AUTOSAR XML (schema 4-0-3)
standard types defined: Boolean, UInt16, UInt8
package /AUTOSAR_Platform/DataConstrs
  range DC_Boolean: raw 0..1
  range DC_UInt16: raw 0..65535
  range DC_UInt8: raw 0..255
package /PATAC/MSM/ComponentTypes
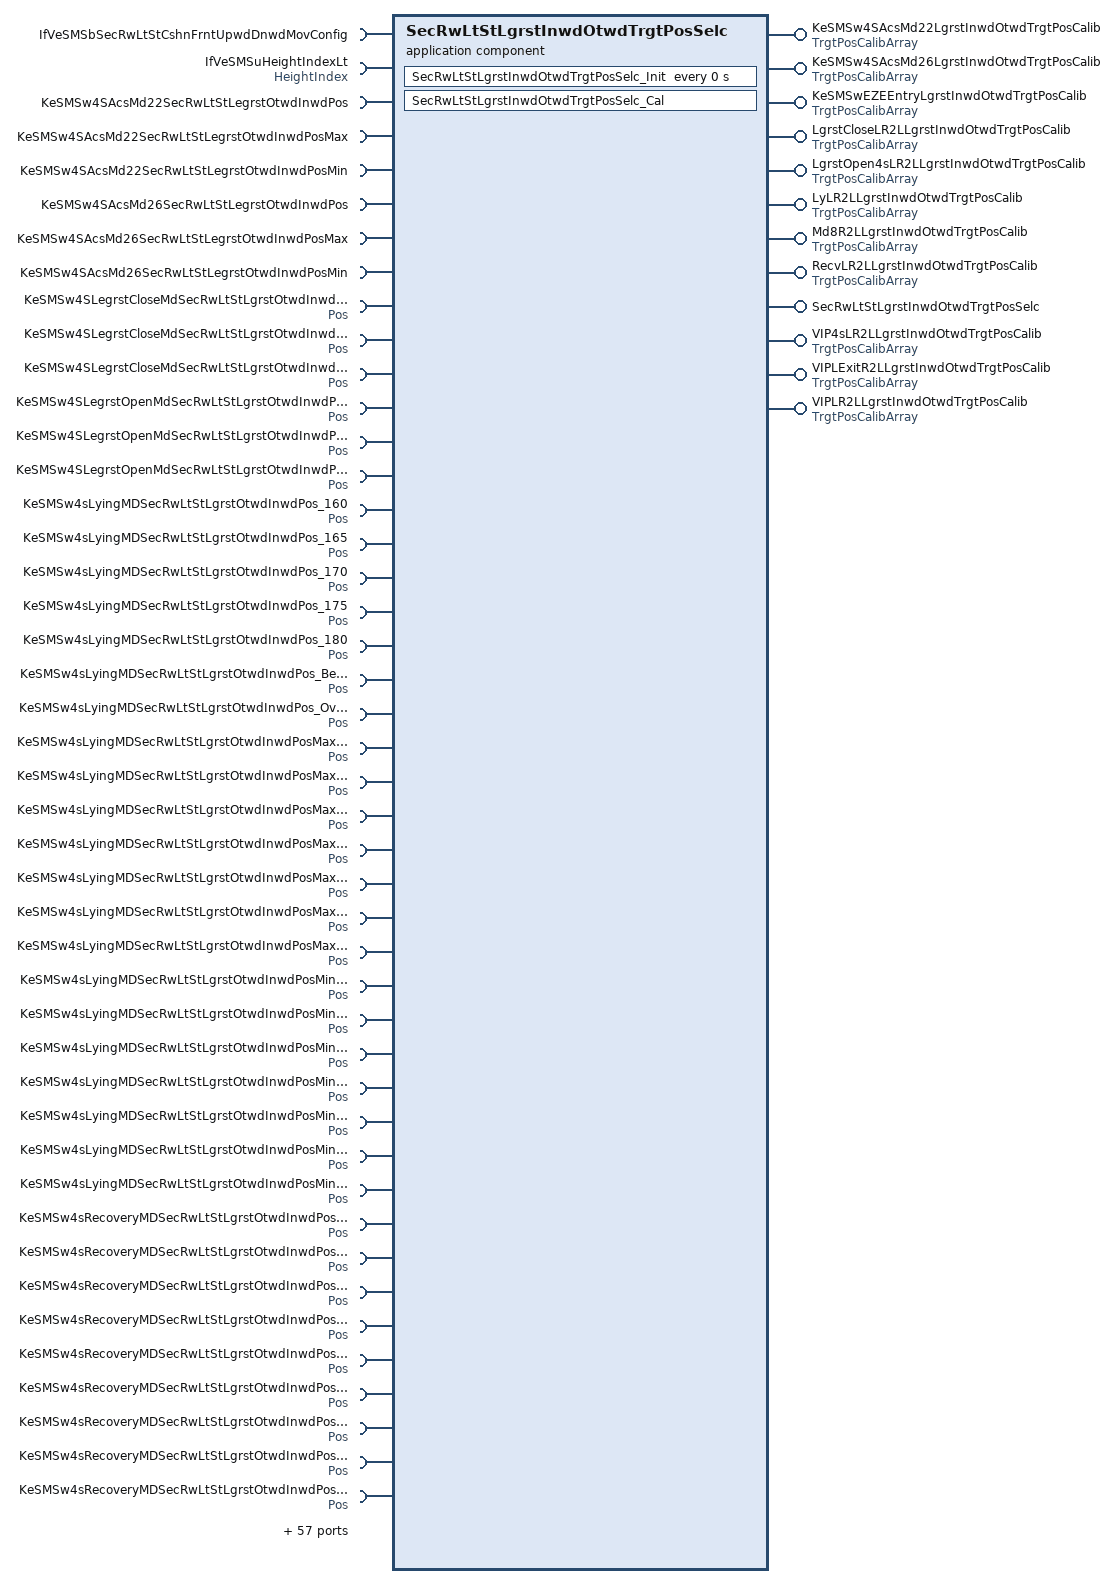
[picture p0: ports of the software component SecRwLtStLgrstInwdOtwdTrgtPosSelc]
  application sw component type SecRwLtStLgrstInwdOtwdTrgtPosSelc
    12 x provide port:
      KeSMSw4SAcsMd22LgrstInwdOtwdTrgtPosCalib: nonqueued-sender-com-spec{data-element=TrgtPosArray, init-value=[4095, 4095, 4095]}, provided-interface=TrgtPosCalibArray
      KeSMSw4SAcsMd26LgrstInwdOtwdTrgtPosCalib: nonqueued-sender-com-spec{data-element=TrgtPosArray, init-value=[4095, 4095, 4095]}, provided-interface=TrgtPosCalibArray
      KeSMSwEZEEntryLgrstInwdOtwdTrgtPosCalib: nonqueued-sender-com-spec{data-element=TrgtPosArray, init-value=[4095, 4095, 4095]}, provided-interface=TrgtPosCalibArray
      LgrstCloseLR2LLgrstInwdOtwdTrgtPosCalib: nonqueued-sender-com-spec{data-element=TrgtPosArray, init-value=[4095, 4095, 4095]}, provided-interface=TrgtPosCalibArray
      LgrstOpen4sLR2LLgrstInwdOtwdTrgtPosCalib: nonqueued-sender-com-spec{data-element=TrgtPosArray, init-value=[4095, 4095, 4095]}, provided-interface=TrgtPosCalibArray
      LyLR2LLgrstInwdOtwdTrgtPosCalib: nonqueued-sender-com-spec{data-element=TrgtPosArray, init-value=[4095, 4095, 4095]}, provided-interface=TrgtPosCalibArray
      Md8R2LLgrstInwdOtwdTrgtPosCalib: nonqueued-sender-com-spec{data-element=TrgtPosArray, init-value=[4095, 4095, 4095]}, provided-interface=TrgtPosCalibArray
      RecvLR2LLgrstInwdOtwdTrgtPosCalib: nonqueued-sender-com-spec{data-element=TrgtPosArray, init-value=[4095, 4095, 4095]}, provided-interface=TrgtPosCalibArray
      SecRwLtStLgrstInwdOtwdTrgtPosSelc: server-com-spec{operation=Cal, queue-length=1}, provided-interface=SecRwLtStLgrstInwdOtwdTrgtPosSelc
      VIP4sLR2LLgrstInwdOtwdTrgtPosCalib: nonqueued-sender-com-spec{data-element=TrgtPosArray, init-value=[4095, 4095, 4095]}, provided-interface=TrgtPosCalibArray
      VIPLExitR2LLgrstInwdOtwdTrgtPosCalib: nonqueued-sender-com-spec{data-element=TrgtPosArray, init-value=[4095, 4095, 4095]}, provided-interface=TrgtPosCalibArray
      VIPLR2LLgrstInwdOtwdTrgtPosCalib: nonqueued-sender-com-spec{data-element=TrgtPosArray, init-value=[4095, 4095, 4095]}, provided-interface=TrgtPosCalibArray
    101 x require port:
      IfVeSMSbSecRwLtStCshnFrntUpwdDnwdMovConfig: nonqueued-receiver-com-spec{data-element=IfVeSMSbSecRwLtStCshnFrntUpwdDnwdMovConfig/Val, filter=data-filter-type=ALWAYS, init-value=0}, required-interface=IfVeSMSbSecRwLtStCshnFrntUpwdDnwdMovConfig
      IfVeSMSuHeightIndexLt: nonqueued-receiver-com-spec{data-element=HeightIndex/Val, filter=data-filter-type=ALWAYS, init-value=0}, required-interface=HeightIndex
      KeSMSw4SAcsMd22SecRwLtStLegrstOtwdInwdPos: parameter-require-com-spec{init-value=0, parameter=KeSMSw4SAcsMd22SecRwLtStLegrstOtwdInwdPos/Val}, required-interface=KeSMSw4SAcsMd22SecRwLtStLegrstOtwdInwdPos
      KeSMSw4SAcsMd22SecRwLtStLegrstOtwdInwdPosMax: parameter-require-com-spec{init-value=0, parameter=KeSMSw4SAcsMd22SecRwLtStLegrstOtwdInwdPosMax/Val}, required-interface=KeSMSw4SAcsMd22SecRwLtStLegrstOtwdInwdPosMax
      KeSMSw4SAcsMd22SecRwLtStLegrstOtwdInwdPosMin: parameter-require-com-spec{init-value=0, parameter=KeSMSw4SAcsMd22SecRwLtStLegrstOtwdInwdPosMin/Val}, required-interface=KeSMSw4SAcsMd22SecRwLtStLegrstOtwdInwdPosMin
      KeSMSw4SAcsMd26SecRwLtStLegrstOtwdInwdPos: parameter-require-com-spec{init-value=0, parameter=KeSMSw4SAcsMd26SecRwLtStLegrstOtwdInwdPos/Val}, required-interface=KeSMSw4SAcsMd26SecRwLtStLegrstOtwdInwdPos
      KeSMSw4SAcsMd26SecRwLtStLegrstOtwdInwdPosMax: parameter-require-com-spec{init-value=0, parameter=KeSMSw4SAcsMd26SecRwLtStLegrstOtwdInwdPosMax/Val}, required-interface=KeSMSw4SAcsMd26SecRwLtStLegrstOtwdInwdPosMax
      KeSMSw4SAcsMd26SecRwLtStLegrstOtwdInwdPosMin: parameter-require-com-spec{init-value=0, parameter=KeSMSw4SAcsMd26SecRwLtStLegrstOtwdInwdPosMin/Val}, required-interface=KeSMSw4SAcsMd26SecRwLtStLegrstOtwdInwdPosMin
      KeSMSw4SLegrstCloseMdSecRwLtStLgrstOtwdInwdPos: parameter-require-com-spec{init-value=0, parameter=Pos/Val}, required-interface=Pos
      KeSMSw4SLegrstCloseMdSecRwLtStLgrstOtwdInwdPosMax: parameter-require-com-spec{init-value=0, parameter=Pos/Val}, required-interface=Pos
      KeSMSw4SLegrstCloseMdSecRwLtStLgrstOtwdInwdPosMin: parameter-require-com-spec{init-value=0, parameter=Pos/Val}, required-interface=Pos
      KeSMSw4SLegrstOpenMdSecRwLtStLgrstOtwdInwdPos: parameter-require-com-spec{init-value=0, parameter=Pos/Val}, required-interface=Pos
      KeSMSw4SLegrstOpenMdSecRwLtStLgrstOtwdInwdPosMax: parameter-require-com-spec{init-value=0, parameter=Pos/Val}, required-interface=Pos
      KeSMSw4SLegrstOpenMdSecRwLtStLgrstOtwdInwdPosMin: parameter-require-com-spec{init-value=0, parameter=Pos/Val}, required-interface=Pos
      KeSMSw4sLyingMDSecRwLtStLgrstOtwdInwdPos_160: parameter-require-com-spec{init-value=0, parameter=Pos/Val}, required-interface=Pos
      KeSMSw4sLyingMDSecRwLtStLgrstOtwdInwdPos_165: parameter-require-com-spec{init-value=0, parameter=Pos/Val}, required-interface=Pos
      KeSMSw4sLyingMDSecRwLtStLgrstOtwdInwdPos_170: parameter-require-com-spec{init-value=0, parameter=Pos/Val}, required-interface=Pos
      KeSMSw4sLyingMDSecRwLtStLgrstOtwdInwdPos_175: parameter-require-com-spec{init-value=0, parameter=Pos/Val}, required-interface=Pos
      KeSMSw4sLyingMDSecRwLtStLgrstOtwdInwdPos_180: parameter-require-com-spec{init-value=0, parameter=Pos/Val}, required-interface=Pos
      KeSMSw4sLyingMDSecRwLtStLgrstOtwdInwdPos_Below160: parameter-require-com-spec{init-value=0, parameter=Pos/Val}, required-interface=Pos
      KeSMSw4sLyingMDSecRwLtStLgrstOtwdInwdPos_Over180: parameter-require-com-spec{init-value=0, parameter=Pos/Val}, required-interface=Pos
      KeSMSw4sLyingMDSecRwLtStLgrstOtwdInwdPosMax_160: parameter-require-com-spec{init-value=0, parameter=Pos/Val}, required-interface=Pos
      KeSMSw4sLyingMDSecRwLtStLgrstOtwdInwdPosMax_165: parameter-require-com-spec{init-value=0, parameter=Pos/Val}, required-interface=Pos
      KeSMSw4sLyingMDSecRwLtStLgrstOtwdInwdPosMax_170: parameter-require-com-spec{init-value=0, parameter=Pos/Val}, required-interface=Pos
      KeSMSw4sLyingMDSecRwLtStLgrstOtwdInwdPosMax_175: parameter-require-com-spec{init-value=0, parameter=Pos/Val}, required-interface=Pos
      KeSMSw4sLyingMDSecRwLtStLgrstOtwdInwdPosMax_180: parameter-require-com-spec{init-value=0, parameter=Pos/Val}, required-interface=Pos
      KeSMSw4sLyingMDSecRwLtStLgrstOtwdInwdPosMax_Below160: parameter-require-com-spec{init-value=0, parameter=Pos/Val}, required-interface=Pos
      KeSMSw4sLyingMDSecRwLtStLgrstOtwdInwdPosMax_Over180: parameter-require-com-spec{init-value=0, parameter=Pos/Val}, required-interface=Pos
      KeSMSw4sLyingMDSecRwLtStLgrstOtwdInwdPosMin_160: parameter-require-com-spec{init-value=0, parameter=Pos/Val}, required-interface=Pos
      KeSMSw4sLyingMDSecRwLtStLgrstOtwdInwdPosMin_165: parameter-require-com-spec{init-value=0, parameter=Pos/Val}, required-interface=Pos
      KeSMSw4sLyingMDSecRwLtStLgrstOtwdInwdPosMin_170: parameter-require-com-spec{init-value=0, parameter=Pos/Val}, required-interface=Pos
      KeSMSw4sLyingMDSecRwLtStLgrstOtwdInwdPosMin_175: parameter-require-com-spec{init-value=0, parameter=Pos/Val}, required-interface=Pos
      KeSMSw4sLyingMDSecRwLtStLgrstOtwdInwdPosMin_180: parameter-require-com-spec{init-value=0, parameter=Pos/Val}, required-interface=Pos
      KeSMSw4sLyingMDSecRwLtStLgrstOtwdInwdPosMin_Below160: parameter-require-com-spec{init-value=0, parameter=Pos/Val}, required-interface=Pos
      KeSMSw4sLyingMDSecRwLtStLgrstOtwdInwdPosMin_Over180: parameter-require-com-spec{init-value=0, parameter=Pos/Val}, required-interface=Pos
      KeSMSw4sRecoveryMDSecRwLtStLgrstOtwdInwdPos_160: parameter-require-com-spec{init-value=0, parameter=Pos/Val}, required-interface=Pos
      KeSMSw4sRecoveryMDSecRwLtStLgrstOtwdInwdPos_165: parameter-require-com-spec{init-value=0, parameter=Pos/Val}, required-interface=Pos
      KeSMSw4sRecoveryMDSecRwLtStLgrstOtwdInwdPos_170: parameter-require-com-spec{init-value=0, parameter=Pos/Val}, required-interface=Pos
      KeSMSw4sRecoveryMDSecRwLtStLgrstOtwdInwdPos_175: parameter-require-com-spec{init-value=0, parameter=Pos/Val}, required-interface=Pos
      KeSMSw4sRecoveryMDSecRwLtStLgrstOtwdInwdPos_180: parameter-require-com-spec{init-value=0, parameter=Pos/Val}, required-interface=Pos
      KeSMSw4sRecoveryMDSecRwLtStLgrstOtwdInwdPos_Below160: parameter-require-com-spec{init-value=0, parameter=Pos/Val}, required-interface=Pos
      KeSMSw4sRecoveryMDSecRwLtStLgrstOtwdInwdPos_Over180: parameter-require-com-spec{init-value=0, parameter=Pos/Val}, required-interface=Pos
      KeSMSw4sRecoveryMDSecRwLtStLgrstOtwdInwdPosMax_160: parameter-require-com-spec{init-value=0, parameter=Pos/Val}, required-interface=Pos
      KeSMSw4sRecoveryMDSecRwLtStLgrstOtwdInwdPosMax_165: parameter-require-com-spec{init-value=0, parameter=Pos/Val}, required-interface=Pos
      KeSMSw4sRecoveryMDSecRwLtStLgrstOtwdInwdPosMax_170: parameter-require-com-spec{init-value=0, parameter=Pos/Val}, required-interface=Pos
      KeSMSw4sRecoveryMDSecRwLtStLgrstOtwdInwdPosMax_175: parameter-require-com-spec{init-value=0, parameter=Pos/Val}, required-interface=Pos
      KeSMSw4sRecoveryMDSecRwLtStLgrstOtwdInwdPosMax_180: parameter-require-com-spec{init-value=0, parameter=Pos/Val}, required-interface=Pos
      KeSMSw4sRecoveryMDSecRwLtStLgrstOtwdInwdPosMax_Below160: parameter-require-com-spec{init-value=0, parameter=Pos/Val}, required-interface=Pos
      KeSMSw4sRecoveryMDSecRwLtStLgrstOtwdInwdPosMax_Over180: parameter-require-com-spec{init-value=0, parameter=Pos/Val}, required-interface=Pos
      KeSMSw4sRecoveryMDSecRwLtStLgrstOtwdInwdPosMin_160: parameter-require-com-spec{init-value=0, parameter=Pos/Val}, required-interface=Pos
      KeSMSw4sRecoveryMDSecRwLtStLgrstOtwdInwdPosMin_165: parameter-require-com-spec{init-value=0, parameter=Pos/Val}, required-interface=Pos
      KeSMSw4sRecoveryMDSecRwLtStLgrstOtwdInwdPosMin_170: parameter-require-com-spec{init-value=0, parameter=Pos/Val}, required-interface=Pos
      KeSMSw4sRecoveryMDSecRwLtStLgrstOtwdInwdPosMin_175: parameter-require-com-spec{init-value=0, parameter=Pos/Val}, required-interface=Pos
      KeSMSw4sRecoveryMDSecRwLtStLgrstOtwdInwdPosMin_180: parameter-require-com-spec{init-value=0, parameter=Pos/Val}, required-interface=Pos
      KeSMSw4sRecoveryMDSecRwLtStLgrstOtwdInwdPosMin_Below160: parameter-require-com-spec{init-value=0, parameter=Pos/Val}, required-interface=Pos
      KeSMSw4sRecoveryMDSecRwLtStLgrstOtwdInwdPosMin_Over180: parameter-require-com-spec{init-value=0, parameter=Pos/Val}, required-interface=Pos
      KeSMSw4sVIPMDSecRwLtStLgrstOtwdInwdPos_160: parameter-require-com-spec{init-value=0, parameter=Pos/Val}, required-interface=Pos
      KeSMSw4sVIPMDSecRwLtStLgrstOtwdInwdPos_165: parameter-require-com-spec{init-value=0, parameter=Pos/Val}, required-interface=Pos
      KeSMSw4sVIPMDSecRwLtStLgrstOtwdInwdPos_170: parameter-require-com-spec{init-value=0, parameter=Pos/Val}, required-interface=Pos
      KeSMSw4sVIPMDSecRwLtStLgrstOtwdInwdPos_175: parameter-require-com-spec{init-value=0, parameter=Pos/Val}, required-interface=Pos
      KeSMSw4sVIPMDSecRwLtStLgrstOtwdInwdPos_180: parameter-require-com-spec{init-value=0, parameter=Pos/Val}, required-interface=Pos
      KeSMSw4sVIPMDSecRwLtStLgrstOtwdInwdPos_Below160: parameter-require-com-spec{init-value=0, parameter=Pos/Val}, required-interface=Pos
      KeSMSw4sVIPMDSecRwLtStLgrstOtwdInwdPos_Over180: parameter-require-com-spec{init-value=0, parameter=Pos/Val}, required-interface=Pos
      KeSMSw4sVIPMDSecRwLtStLgrstOtwdInwdPosMax_160: parameter-require-com-spec{init-value=0, parameter=Pos/Val}, required-interface=Pos
      KeSMSw4sVIPMDSecRwLtStLgrstOtwdInwdPosMax_165: parameter-require-com-spec{init-value=0, parameter=Pos/Val}, required-interface=Pos
      KeSMSw4sVIPMDSecRwLtStLgrstOtwdInwdPosMax_170: parameter-require-com-spec{init-value=0, parameter=Pos/Val}, required-interface=Pos
      KeSMSw4sVIPMDSecRwLtStLgrstOtwdInwdPosMax_175: parameter-require-com-spec{init-value=0, parameter=Pos/Val}, required-interface=Pos
      KeSMSw4sVIPMDSecRwLtStLgrstOtwdInwdPosMax_180: parameter-require-com-spec{init-value=0, parameter=Pos/Val}, required-interface=Pos
      KeSMSw4sVIPMDSecRwLtStLgrstOtwdInwdPosMax_Below160: parameter-require-com-spec{init-value=0, parameter=Pos/Val}, required-interface=Pos
      KeSMSw4sVIPMDSecRwLtStLgrstOtwdInwdPosMax_Over180: parameter-require-com-spec{init-value=0, parameter=Pos/Val}, required-interface=Pos
      KeSMSw4sVIPMDSecRwLtStLgrstOtwdInwdPosMin_160: parameter-require-com-spec{init-value=0, parameter=Pos/Val}, required-interface=Pos
      KeSMSw4sVIPMDSecRwLtStLgrstOtwdInwdPosMin_165: parameter-require-com-spec{init-value=0, parameter=Pos/Val}, required-interface=Pos
      KeSMSw4sVIPMDSecRwLtStLgrstOtwdInwdPosMin_170: parameter-require-com-spec{init-value=0, parameter=Pos/Val}, required-interface=Pos
      KeSMSw4sVIPMDSecRwLtStLgrstOtwdInwdPosMin_175: parameter-require-com-spec{init-value=0, parameter=Pos/Val}, required-interface=Pos
      KeSMSw4sVIPMDSecRwLtStLgrstOtwdInwdPosMin_180: parameter-require-com-spec{init-value=0, parameter=Pos/Val}, required-interface=Pos
      KeSMSw4sVIPMDSecRwLtStLgrstOtwdInwdPosMin_Below160: parameter-require-com-spec{init-value=0, parameter=Pos/Val}, required-interface=Pos
      KeSMSw4sVIPMDSecRwLtStLgrstOtwdInwdPosMin_Over180: parameter-require-com-spec{init-value=0, parameter=Pos/Val}, required-interface=Pos
      KeSMSw6sAcsEntrySecRwLtStLgrstInwdOtwdPos: parameter-require-com-spec{init-value=4095, parameter=Pos/Val}, required-interface=Pos
      KeSMSw6sAcsEntrySecRwLtStLgrstInwdOtwdPosMax: parameter-require-com-spec{init-value=4095, parameter=Pos/Val}, required-interface=Pos
      KeSMSw6sAcsEntrySecRwLtStLgrstInwdOtwdPosMin: parameter-require-com-spec{init-value=4095, parameter=Pos/Val}, required-interface=Pos
      KeSMSw6sRecoveryMdSecRwLtStLgrstInwdOtwdPos: parameter-require-com-spec{init-value=4095, parameter=Pos/Val}, required-interface=Pos
      KeSMSw6sRecoveryMdSecRwLtStLgrstInwdOtwdPosMax: parameter-require-com-spec{init-value=4095, parameter=Pos/Val}, required-interface=Pos
      KeSMSw6sRecoveryMdSecRwLtStLgrstInwdOtwdPosMin: parameter-require-com-spec{init-value=4095, parameter=Pos/Val}, required-interface=Pos
      KeSMSw6SVIPMdSecRwLtStLgrstInwdOtwdPos: parameter-require-com-spec{init-value=4095, parameter=Pos/Val}, required-interface=Pos
      KeSMSw6SVIPMdSecRwLtStLgrstInwdOtwdPosMax: parameter-require-com-spec{init-value=4095, parameter=Pos/Val}, required-interface=Pos
      KeSMSw6SVIPMdSecRwLtStLgrstInwdOtwdPosMin: parameter-require-com-spec{init-value=4095, parameter=Pos/Val}, required-interface=Pos
      KeSMSwAcsEntrySecRwLtStLgrstInwdOtwdPos: parameter-require-com-spec{init-value=4095, parameter=Pos/Val}, required-interface=Pos
      KeSMSwAcsEntrySecRwLtStLgrstInwdOtwdPosMax: parameter-require-com-spec{init-value=4095, parameter=Pos/Val}, required-interface=Pos
      KeSMSwAcsEntrySecRwLtStLgrstInwdOtwdPosMin: parameter-require-com-spec{init-value=4095, parameter=Pos/Val}, required-interface=Pos
      KeSMSwAcsMd8SecRwLtStLgrstInwdOtwdPos: parameter-require-com-spec{init-value=0, parameter=Pos/Val}, required-interface=Pos
      KeSMSwAcsMd8SecRwLtStLgrstInwdOtwdPosMax: parameter-require-com-spec{init-value=0, parameter=Pos/Val}, required-interface=Pos
      KeSMSwAcsMd8SecRwLtStLgrstInwdOtwdPosMin: parameter-require-com-spec{init-value=0, parameter=Pos/Val}, required-interface=Pos
      KeSMSwRecoveryMdSecRwLtStLgrstInwdOtwdPos: parameter-require-com-spec{init-value=4095, parameter=Pos/Val}, required-interface=Pos
      KeSMSwRecoveryMdSecRwLtStLgrstInwdOtwdPosMax: parameter-require-com-spec{init-value=4095, parameter=Pos/Val}, required-interface=Pos
      KeSMSwRecoveryMdSecRwLtStLgrstInwdOtwdPosMin: parameter-require-com-spec{init-value=4095, parameter=Pos/Val}, required-interface=Pos
      KeSMSwVIPMdSecRwLtStLgrstInwdOtwdPos: parameter-require-com-spec{init-value=4095, parameter=Pos/Val}, required-interface=Pos
      KeSMSwVIPMdSecRwLtStLgrstInwdOtwdPosMax: parameter-require-com-spec{init-value=4095, parameter=Pos/Val}, required-interface=Pos
      KeSMSwVIPMdSecRwLtStLgrstInwdOtwdPosMin: parameter-require-com-spec{init-value=4095, parameter=Pos/Val}, required-interface=Pos
      StNumFlg: required-interface=StNumFlg
        required-com-specs:
          data-element=Is4s, filter=data-filter-type=ALWAYS, init-value=0
          data-element=Is6s, filter=data-filter-type=ALWAYS, init-value=0
          data-element=Is6s7s, filter=data-filter-type=ALWAYS, init-value=0
          data-element=Is7s, filter=data-filter-type=ALWAYS, init-value=0
      VIPL557TrgtPos: required-com-specs=[VIPL557TrgtPos/Get, VIPL557TrgtPos/Set], required-interface=VIPL557TrgtPos
      VIPLExit557TrgtPos: required-com-specs=[VIPLExit557TrgtPos/Get, VIPLExit557TrgtPos/Set], required-interface=VIPLExit557TrgtPos
    behavior SecRwLtStLgrstInwdOtwdTrgtPosSelc_InternalBehavior
      operation invoked event OIT_SecRwLtStLgrstInwdOtwdTrgtPosSelc_Cal_SecRwLtStLgrstInwdOtwdTrgtPosSelc_Cal: start-on-event=SecRwLtStLgrstInwdOtwdTrgtPosSelc_Cal, operation=SecRwLtStLgrstInwdOtwdTrgtPosSelc.Cal
      timing event SecRwLtStLgrstInwdOtwdTrgtPosSelc_InitEvent: start-on-event=SecRwLtStLgrstInwdOtwdTrgtPosSelc_Init, period=0
      runnable SecRwLtStLgrstInwdOtwdTrgtPosSelc_Cal
        data-receive-point-by-arguments:
          6 x access:
            REC_IfVeSMSbSecRwLtStCshnFrntUpwdDnwdMovConfig_Val: accessed-variable=IfVeSMSbSecRwLtStCshnFrntUpwdDnwdMovConfig.Val
            REC_IfVeSMSuHeightIndexLt_Val: accessed-variable=IfVeSMSuHeightIndexLt.Val
            REC_StNumFlg_Is4s: accessed-variable=StNumFlg.Is4s
            REC_StNumFlg_Is6s: accessed-variable=StNumFlg.Is6s
            REC_StNumFlg_Is6s7s: accessed-variable=StNumFlg.Is6s7s
            REC_StNumFlg_Is7s: accessed-variable=StNumFlg.Is7s
        data-send-points:
          11 x access:
            SEND_KeSMSw4SAcsMd22LgrstInwdOtwdTrgtPosCalib_TrgtPosArray: accessed-variable=KeSMSw4SAcsMd22LgrstInwdOtwdTrgtPosCalib.TrgtPosArray
            SEND_KeSMSw4SAcsMd26LgrstInwdOtwdTrgtPosCalib_TrgtPosArray: accessed-variable=KeSMSw4SAcsMd26LgrstInwdOtwdTrgtPosCalib.TrgtPosArray
            SEND_KeSMSwEZEEntryLgrstInwdOtwdTrgtPosCalib_TrgtPosArray: accessed-variable=KeSMSwEZEEntryLgrstInwdOtwdTrgtPosCalib.TrgtPosArray
            SEND_LgrstCloseLR2LLgrstInwdOtwdTrgtPosCalib_TrgtPosArray: accessed-variable=LgrstCloseLR2LLgrstInwdOtwdTrgtPosCalib.TrgtPosArray
            SEND_LgrstOpen4sLR2LLgrstInwdOtwdTrgtPosCalib_TrgtPosArray: accessed-variable=LgrstOpen4sLR2LLgrstInwdOtwdTrgtPosCalib.TrgtPosArray
            SEND_LyLR2LLgrstInwdOtwdTrgtPosCalib_TrgtPosArray: accessed-variable=LyLR2LLgrstInwdOtwdTrgtPosCalib.TrgtPosArray
            SEND_Md8R2LLgrstInwdOtwdTrgtPosCalib_TrgtPosArray: accessed-variable=Md8R2LLgrstInwdOtwdTrgtPosCalib.TrgtPosArray
            SEND_RecvLR2LLgrstInwdOtwdTrgtPosCalib_TrgtPosArray: accessed-variable=RecvLR2LLgrstInwdOtwdTrgtPosCalib.TrgtPosArray
            SEND_VIP4sLR2LLgrstInwdOtwdTrgtPosCalib_TrgtPosArray: accessed-variable=VIP4sLR2LLgrstInwdOtwdTrgtPosCalib.TrgtPosArray
            SEND_VIPLExitR2LLgrstInwdOtwdTrgtPosCalib_TrgtPosArray: accessed-variable=VIPLExitR2LLgrstInwdOtwdTrgtPosCalib.TrgtPosArray
            SEND_VIPLR2LLgrstInwdOtwdTrgtPosCalib_TrgtPosArray: accessed-variable=VIPLR2LLgrstInwdOtwdTrgtPosCalib.TrgtPosArray
        96 x parameter access:
          PA_KeSMSw4SAcsMd22SecRwLtStLegrstOtwdInwdPos_Val: accessed-parameter=KeSMSw4SAcsMd22SecRwLtStLegrstOtwdInwdPos.Val
          PA_KeSMSw4SAcsMd22SecRwLtStLegrstOtwdInwdPosMax_Val: accessed-parameter=KeSMSw4SAcsMd22SecRwLtStLegrstOtwdInwdPosMax.Val
          PA_KeSMSw4SAcsMd22SecRwLtStLegrstOtwdInwdPosMin_Val: accessed-parameter=KeSMSw4SAcsMd22SecRwLtStLegrstOtwdInwdPosMin.Val
          PA_KeSMSw4SAcsMd26SecRwLtStLegrstOtwdInwdPos_Val: accessed-parameter=KeSMSw4SAcsMd26SecRwLtStLegrstOtwdInwdPos.Val
          PA_KeSMSw4SAcsMd26SecRwLtStLegrstOtwdInwdPosMax_Val: accessed-parameter=KeSMSw4SAcsMd26SecRwLtStLegrstOtwdInwdPosMax.Val
          PA_KeSMSw4SAcsMd26SecRwLtStLegrstOtwdInwdPosMin_Val: accessed-parameter=KeSMSw4SAcsMd26SecRwLtStLegrstOtwdInwdPosMin.Val
          PA_KeSMSw4SLegrstCloseMdSecRwLtStLgrstOtwdInwdPos_Val: accessed-parameter=KeSMSw4SLegrstCloseMdSecRwLtStLgrstOtwdInwdPos.Val
          PA_KeSMSw4SLegrstCloseMdSecRwLtStLgrstOtwdInwdPosMax_Val: accessed-parameter=KeSMSw4SLegrstCloseMdSecRwLtStLgrstOtwdInwdPosMax.Val
          PA_KeSMSw4SLegrstCloseMdSecRwLtStLgrstOtwdInwdPosMin_Val: accessed-parameter=KeSMSw4SLegrstCloseMdSecRwLtStLgrstOtwdInwdPosMin.Val
          PA_KeSMSw4SLegrstOpenMdSecRwLtStLgrstOtwdInwdPos_Val: accessed-parameter=KeSMSw4SLegrstOpenMdSecRwLtStLgrstOtwdInwdPos.Val
          PA_KeSMSw4SLegrstOpenMdSecRwLtStLgrstOtwdInwdPosMax_Val: accessed-parameter=KeSMSw4SLegrstOpenMdSecRwLtStLgrstOtwdInwdPosMax.Val
          PA_KeSMSw4SLegrstOpenMdSecRwLtStLgrstOtwdInwdPosMin_Val: accessed-parameter=KeSMSw4SLegrstOpenMdSecRwLtStLgrstOtwdInwdPosMin.Val
          PA_KeSMSw4sLyingMDSecRwLtStLgrstOtwdInwdPos_160_Val: accessed-parameter=KeSMSw4sLyingMDSecRwLtStLgrstOtwdInwdPos_160.Val
          PA_KeSMSw4sLyingMDSecRwLtStLgrstOtwdInwdPos_165_Val: accessed-parameter=KeSMSw4sLyingMDSecRwLtStLgrstOtwdInwdPos_165.Val
          PA_KeSMSw4sLyingMDSecRwLtStLgrstOtwdInwdPos_170_Val: accessed-parameter=KeSMSw4sLyingMDSecRwLtStLgrstOtwdInwdPos_170.Val
          PA_KeSMSw4sLyingMDSecRwLtStLgrstOtwdInwdPos_175_Val: accessed-parameter=KeSMSw4sLyingMDSecRwLtStLgrstOtwdInwdPos_175.Val
          PA_KeSMSw4sLyingMDSecRwLtStLgrstOtwdInwdPos_180_Val: accessed-parameter=KeSMSw4sLyingMDSecRwLtStLgrstOtwdInwdPos_180.Val
          PA_KeSMSw4sLyingMDSecRwLtStLgrstOtwdInwdPos_Below160_Val: accessed-parameter=KeSMSw4sLyingMDSecRwLtStLgrstOtwdInwdPos_Below160.Val
          PA_KeSMSw4sLyingMDSecRwLtStLgrstOtwdInwdPos_Over180_Val: accessed-parameter=KeSMSw4sLyingMDSecRwLtStLgrstOtwdInwdPos_Over180.Val
          PA_KeSMSw4sLyingMDSecRwLtStLgrstOtwdInwdPosMax_160_Val: accessed-parameter=KeSMSw4sLyingMDSecRwLtStLgrstOtwdInwdPosMax_160.Val
          PA_KeSMSw4sLyingMDSecRwLtStLgrstOtwdInwdPosMax_165_Val: accessed-parameter=KeSMSw4sLyingMDSecRwLtStLgrstOtwdInwdPosMax_165.Val
          PA_KeSMSw4sLyingMDSecRwLtStLgrstOtwdInwdPosMax_170_Val: accessed-parameter=KeSMSw4sLyingMDSecRwLtStLgrstOtwdInwdPosMax_170.Val
          PA_KeSMSw4sLyingMDSecRwLtStLgrstOtwdInwdPosMax_175_Val: accessed-parameter=KeSMSw4sLyingMDSecRwLtStLgrstOtwdInwdPosMax_175.Val
          PA_KeSMSw4sLyingMDSecRwLtStLgrstOtwdInwdPosMax_180_Val: accessed-parameter=KeSMSw4sLyingMDSecRwLtStLgrstOtwdInwdPosMax_180.Val
          PA_KeSMSw4sLyingMDSecRwLtStLgrstOtwdInwdPosMax_Below160_Val: accessed-parameter=KeSMSw4sLyingMDSecRwLtStLgrstOtwdInwdPosMax_Below160.Val
          PA_KeSMSw4sLyingMDSecRwLtStLgrstOtwdInwdPosMax_Over180_Val: accessed-parameter=KeSMSw4sLyingMDSecRwLtStLgrstOtwdInwdPosMax_Over180.Val
          PA_KeSMSw4sLyingMDSecRwLtStLgrstOtwdInwdPosMin_160_Val: accessed-parameter=KeSMSw4sLyingMDSecRwLtStLgrstOtwdInwdPosMin_160.Val
          PA_KeSMSw4sLyingMDSecRwLtStLgrstOtwdInwdPosMin_165_Val: accessed-parameter=KeSMSw4sLyingMDSecRwLtStLgrstOtwdInwdPosMin_165.Val
          PA_KeSMSw4sLyingMDSecRwLtStLgrstOtwdInwdPosMin_170_Val: accessed-parameter=KeSMSw4sLyingMDSecRwLtStLgrstOtwdInwdPosMin_170.Val
          PA_KeSMSw4sLyingMDSecRwLtStLgrstOtwdInwdPosMin_175_Val: accessed-parameter=KeSMSw4sLyingMDSecRwLtStLgrstOtwdInwdPosMin_175.Val
          PA_KeSMSw4sLyingMDSecRwLtStLgrstOtwdInwdPosMin_180_Val: accessed-parameter=KeSMSw4sLyingMDSecRwLtStLgrstOtwdInwdPosMin_180.Val
          PA_KeSMSw4sLyingMDSecRwLtStLgrstOtwdInwdPosMin_Below160_Val: accessed-parameter=KeSMSw4sLyingMDSecRwLtStLgrstOtwdInwdPosMin_Below160.Val
          PA_KeSMSw4sLyingMDSecRwLtStLgrstOtwdInwdPosMin_Over180_Val: accessed-parameter=KeSMSw4sLyingMDSecRwLtStLgrstOtwdInwdPosMin_Over180.Val
          PA_KeSMSw4sRecoveryMDSecRwLtStLgrstOtwdInwdPos_160_Val: accessed-parameter=KeSMSw4sRecoveryMDSecRwLtStLgrstOtwdInwdPos_160.Val
          PA_KeSMSw4sRecoveryMDSecRwLtStLgrstOtwdInwdPos_165_Val: accessed-parameter=KeSMSw4sRecoveryMDSecRwLtStLgrstOtwdInwdPos_165.Val
          PA_KeSMSw4sRecoveryMDSecRwLtStLgrstOtwdInwdPos_170_Val: accessed-parameter=KeSMSw4sRecoveryMDSecRwLtStLgrstOtwdInwdPos_170.Val
          PA_KeSMSw4sRecoveryMDSecRwLtStLgrstOtwdInwdPos_175_Val: accessed-parameter=KeSMSw4sRecoveryMDSecRwLtStLgrstOtwdInwdPos_175.Val
          PA_KeSMSw4sRecoveryMDSecRwLtStLgrstOtwdInwdPos_180_Val: accessed-parameter=KeSMSw4sRecoveryMDSecRwLtStLgrstOtwdInwdPos_180.Val
          PA_KeSMSw4sRecoveryMDSecRwLtStLgrstOtwdInwdPos_Below160_Val: accessed-parameter=KeSMSw4sRecoveryMDSecRwLtStLgrstOtwdInwdPos_Below160.Val
          PA_KeSMSw4sRecoveryMDSecRwLtStLgrstOtwdInwdPos_Over180_Val: accessed-parameter=KeSMSw4sRecoveryMDSecRwLtStLgrstOtwdInwdPos_Over180.Val
          PA_KeSMSw4sRecoveryMDSecRwLtStLgrstOtwdInwdPosMax_160_Val: accessed-parameter=KeSMSw4sRecoveryMDSecRwLtStLgrstOtwdInwdPosMax_160.Val
          PA_KeSMSw4sRecoveryMDSecRwLtStLgrstOtwdInwdPosMax_165_Val: accessed-parameter=KeSMSw4sRecoveryMDSecRwLtStLgrstOtwdInwdPosMax_165.Val
          PA_KeSMSw4sRecoveryMDSecRwLtStLgrstOtwdInwdPosMax_170_Val: accessed-parameter=KeSMSw4sRecoveryMDSecRwLtStLgrstOtwdInwdPosMax_170.Val
          PA_KeSMSw4sRecoveryMDSecRwLtStLgrstOtwdInwdPosMax_175_Val: accessed-parameter=KeSMSw4sRecoveryMDSecRwLtStLgrstOtwdInwdPosMax_175.Val
          PA_KeSMSw4sRecoveryMDSecRwLtStLgrstOtwdInwdPosMax_180_Val: accessed-parameter=KeSMSw4sRecoveryMDSecRwLtStLgrstOtwdInwdPosMax_180.Val
          PA_KeSMSw4sRecoveryMDSecRwLtStLgrstOtwdInwdPosMax_Below160_Val: accessed-parameter=KeSMSw4sRecoveryMDSecRwLtStLgrstOtwdInwdPosMax_Below160.Val
          PA_KeSMSw4sRecoveryMDSecRwLtStLgrstOtwdInwdPosMax_Over180_Val: accessed-parameter=KeSMSw4sRecoveryMDSecRwLtStLgrstOtwdInwdPosMax_Over180.Val
          PA_KeSMSw4sRecoveryMDSecRwLtStLgrstOtwdInwdPosMin_160_Val: accessed-parameter=KeSMSw4sRecoveryMDSecRwLtStLgrstOtwdInwdPosMin_160.Val
          PA_KeSMSw4sRecoveryMDSecRwLtStLgrstOtwdInwdPosMin_165_Val: accessed-parameter=KeSMSw4sRecoveryMDSecRwLtStLgrstOtwdInwdPosMin_165.Val
          PA_KeSMSw4sRecoveryMDSecRwLtStLgrstOtwdInwdPosMin_170_Val: accessed-parameter=KeSMSw4sRecoveryMDSecRwLtStLgrstOtwdInwdPosMin_170.Val
          PA_KeSMSw4sRecoveryMDSecRwLtStLgrstOtwdInwdPosMin_175_Val: accessed-parameter=KeSMSw4sRecoveryMDSecRwLtStLgrstOtwdInwdPosMin_175.Val
          PA_KeSMSw4sRecoveryMDSecRwLtStLgrstOtwdInwdPosMin_180_Val: accessed-parameter=KeSMSw4sRecoveryMDSecRwLtStLgrstOtwdInwdPosMin_180.Val
          PA_KeSMSw4sRecoveryMDSecRwLtStLgrstOtwdInwdPosMin_Below160_Val: accessed-parameter=KeSMSw4sRecoveryMDSecRwLtStLgrstOtwdInwdPosMin_Below160.Val
          PA_KeSMSw4sRecoveryMDSecRwLtStLgrstOtwdInwdPosMin_Over180_Val: accessed-parameter=KeSMSw4sRecoveryMDSecRwLtStLgrstOtwdInwdPosMin_Over180.Val
          PA_KeSMSw4sVIPMDSecRwLtStLgrstOtwdInwdPos_160_Val: accessed-parameter=KeSMSw4sVIPMDSecRwLtStLgrstOtwdInwdPos_160.Val
          PA_KeSMSw4sVIPMDSecRwLtStLgrstOtwdInwdPos_165_Val: accessed-parameter=KeSMSw4sVIPMDSecRwLtStLgrstOtwdInwdPos_165.Val
          PA_KeSMSw4sVIPMDSecRwLtStLgrstOtwdInwdPos_170_Val: accessed-parameter=KeSMSw4sVIPMDSecRwLtStLgrstOtwdInwdPos_170.Val
          PA_KeSMSw4sVIPMDSecRwLtStLgrstOtwdInwdPos_175_Val: accessed-parameter=KeSMSw4sVIPMDSecRwLtStLgrstOtwdInwdPos_175.Val
          PA_KeSMSw4sVIPMDSecRwLtStLgrstOtwdInwdPos_180_Val: accessed-parameter=KeSMSw4sVIPMDSecRwLtStLgrstOtwdInwdPos_180.Val
          PA_KeSMSw4sVIPMDSecRwLtStLgrstOtwdInwdPos_Below160_Val: accessed-parameter=KeSMSw4sVIPMDSecRwLtStLgrstOtwdInwdPos_Below160.Val
          PA_KeSMSw4sVIPMDSecRwLtStLgrstOtwdInwdPos_Over180_Val: accessed-parameter=KeSMSw4sVIPMDSecRwLtStLgrstOtwdInwdPos_Over180.Val
          PA_KeSMSw4sVIPMDSecRwLtStLgrstOtwdInwdPosMax_160_Val: accessed-parameter=KeSMSw4sVIPMDSecRwLtStLgrstOtwdInwdPosMax_160.Val
          PA_KeSMSw4sVIPMDSecRwLtStLgrstOtwdInwdPosMax_165_Val: accessed-parameter=KeSMSw4sVIPMDSecRwLtStLgrstOtwdInwdPosMax_165.Val
          PA_KeSMSw4sVIPMDSecRwLtStLgrstOtwdInwdPosMax_170_Val: accessed-parameter=KeSMSw4sVIPMDSecRwLtStLgrstOtwdInwdPosMax_170.Val
          PA_KeSMSw4sVIPMDSecRwLtStLgrstOtwdInwdPosMax_175_Val: accessed-parameter=KeSMSw4sVIPMDSecRwLtStLgrstOtwdInwdPosMax_175.Val
          PA_KeSMSw4sVIPMDSecRwLtStLgrstOtwdInwdPosMax_180_Val: accessed-parameter=KeSMSw4sVIPMDSecRwLtStLgrstOtwdInwdPosMax_180.Val
          PA_KeSMSw4sVIPMDSecRwLtStLgrstOtwdInwdPosMax_Below160_Val: accessed-parameter=KeSMSw4sVIPMDSecRwLtStLgrstOtwdInwdPosMax_Below160.Val
          PA_KeSMSw4sVIPMDSecRwLtStLgrstOtwdInwdPosMax_Over180_Val: accessed-parameter=KeSMSw4sVIPMDSecRwLtStLgrstOtwdInwdPosMax_Over180.Val
          PA_KeSMSw4sVIPMDSecRwLtStLgrstOtwdInwdPosMin_160_Val: accessed-parameter=KeSMSw4sVIPMDSecRwLtStLgrstOtwdInwdPosMin_160.Val
          PA_KeSMSw4sVIPMDSecRwLtStLgrstOtwdInwdPosMin_165_Val: accessed-parameter=KeSMSw4sVIPMDSecRwLtStLgrstOtwdInwdPosMin_165.Val
          PA_KeSMSw4sVIPMDSecRwLtStLgrstOtwdInwdPosMin_170_Val: accessed-parameter=KeSMSw4sVIPMDSecRwLtStLgrstOtwdInwdPosMin_170.Val
          PA_KeSMSw4sVIPMDSecRwLtStLgrstOtwdInwdPosMin_175_Val: accessed-parameter=KeSMSw4sVIPMDSecRwLtStLgrstOtwdInwdPosMin_175.Val
          PA_KeSMSw4sVIPMDSecRwLtStLgrstOtwdInwdPosMin_180_Val: accessed-parameter=KeSMSw4sVIPMDSecRwLtStLgrstOtwdInwdPosMin_180.Val
          PA_KeSMSw4sVIPMDSecRwLtStLgrstOtwdInwdPosMin_Below160_Val: accessed-parameter=KeSMSw4sVIPMDSecRwLtStLgrstOtwdInwdPosMin_Below160.Val
          PA_KeSMSw4sVIPMDSecRwLtStLgrstOtwdInwdPosMin_Over180_Val: accessed-parameter=KeSMSw4sVIPMDSecRwLtStLgrstOtwdInwdPosMin_Over180.Val
          PA_KeSMSw6sAcsEntrySecRwLtStLgrstInwdOtwdPos_Val: accessed-parameter=KeSMSw6sAcsEntrySecRwLtStLgrstInwdOtwdPos.Val
          PA_KeSMSw6sAcsEntrySecRwLtStLgrstInwdOtwdPosMax_Val: accessed-parameter=KeSMSw6sAcsEntrySecRwLtStLgrstInwdOtwdPosMax.Val
          PA_KeSMSw6sAcsEntrySecRwLtStLgrstInwdOtwdPosMin_Val: accessed-parameter=KeSMSw6sAcsEntrySecRwLtStLgrstInwdOtwdPosMin.Val
          PA_KeSMSw6sRecoveryMdSecRwLtStLgrstInwdOtwdPos_Val: accessed-parameter=KeSMSw6sRecoveryMdSecRwLtStLgrstInwdOtwdPos.Val
          PA_KeSMSw6sRecoveryMdSecRwLtStLgrstInwdOtwdPosMax_Val: accessed-parameter=KeSMSw6sRecoveryMdSecRwLtStLgrstInwdOtwdPosMax.Val
          PA_KeSMSw6sRecoveryMdSecRwLtStLgrstInwdOtwdPosMin_Val: accessed-parameter=KeSMSw6sRecoveryMdSecRwLtStLgrstInwdOtwdPosMin.Val
          PA_KeSMSw6SVIPMdSecRwLtStLgrstInwdOtwdPos_Val: accessed-parameter=KeSMSw6SVIPMdSecRwLtStLgrstInwdOtwdPos.Val
          PA_KeSMSw6SVIPMdSecRwLtStLgrstInwdOtwdPosMax_Val: accessed-parameter=KeSMSw6SVIPMdSecRwLtStLgrstInwdOtwdPosMax.Val
          PA_KeSMSw6SVIPMdSecRwLtStLgrstInwdOtwdPosMin_Val: accessed-parameter=KeSMSw6SVIPMdSecRwLtStLgrstInwdOtwdPosMin.Val
          PA_KeSMSwAcsEntrySecRwLtStLgrstInwdOtwdPos_Val: accessed-parameter=KeSMSwAcsEntrySecRwLtStLgrstInwdOtwdPos.Val
          PA_KeSMSwAcsEntrySecRwLtStLgrstInwdOtwdPosMax_Val: accessed-parameter=KeSMSwAcsEntrySecRwLtStLgrstInwdOtwdPosMax.Val
          PA_KeSMSwAcsEntrySecRwLtStLgrstInwdOtwdPosMin_Val: accessed-parameter=KeSMSwAcsEntrySecRwLtStLgrstInwdOtwdPosMin.Val
          PA_KeSMSwAcsMd8SecRwLtStLgrstInwdOtwdPos_Val: accessed-parameter=KeSMSwAcsMd8SecRwLtStLgrstInwdOtwdPos.Val
          PA_KeSMSwAcsMd8SecRwLtStLgrstInwdOtwdPosMax_Val: accessed-parameter=KeSMSwAcsMd8SecRwLtStLgrstInwdOtwdPosMax.Val
          PA_KeSMSwAcsMd8SecRwLtStLgrstInwdOtwdPosMin_Val: accessed-parameter=KeSMSwAcsMd8SecRwLtStLgrstInwdOtwdPosMin.Val
          PA_KeSMSwRecoveryMdSecRwLtStLgrstInwdOtwdPos_Val: accessed-parameter=KeSMSwRecoveryMdSecRwLtStLgrstInwdOtwdPos.Val
          PA_KeSMSwRecoveryMdSecRwLtStLgrstInwdOtwdPosMax_Val: accessed-parameter=KeSMSwRecoveryMdSecRwLtStLgrstInwdOtwdPosMax.Val
          PA_KeSMSwRecoveryMdSecRwLtStLgrstInwdOtwdPosMin_Val: accessed-parameter=KeSMSwRecoveryMdSecRwLtStLgrstInwdOtwdPosMin.Val
          PA_KeSMSwVIPMdSecRwLtStLgrstInwdOtwdPos_Val: accessed-parameter=KeSMSwVIPMdSecRwLtStLgrstInwdOtwdPos.Val
          PA_KeSMSwVIPMdSecRwLtStLgrstInwdOtwdPosMax_Val: accessed-parameter=KeSMSwVIPMdSecRwLtStLgrstInwdOtwdPosMax.Val
          PA_KeSMSwVIPMdSecRwLtStLgrstInwdOtwdPosMin_Val: accessed-parameter=KeSMSwVIPMdSecRwLtStLgrstInwdOtwdPosMin.Val
        sync call SC_VIPL557TrgtPos_Get: operation=VIPL557TrgtPos.Get, timeout=0
        sync call SC_VIPLExit557TrgtPos_Get: operation=VIPLExit557TrgtPos.Get, timeout=0
      runnable SecRwLtStLgrstInwdOtwdTrgtPosSelc_Init
        96 x parameter access:
          PA_KeSMSw4SAcsMd22SecRwLtStLegrstOtwdInwdPos_Val: accessed-parameter=KeSMSw4SAcsMd22SecRwLtStLegrstOtwdInwdPos.Val
          PA_KeSMSw4SAcsMd22SecRwLtStLegrstOtwdInwdPosMax_Val: accessed-parameter=KeSMSw4SAcsMd22SecRwLtStLegrstOtwdInwdPosMax.Val
          PA_KeSMSw4SAcsMd22SecRwLtStLegrstOtwdInwdPosMin_Val: accessed-parameter=KeSMSw4SAcsMd22SecRwLtStLegrstOtwdInwdPosMin.Val
          PA_KeSMSw4SAcsMd26SecRwLtStLegrstOtwdInwdPos_Val: accessed-parameter=KeSMSw4SAcsMd26SecRwLtStLegrstOtwdInwdPos.Val
          PA_KeSMSw4SAcsMd26SecRwLtStLegrstOtwdInwdPosMax_Val: accessed-parameter=KeSMSw4SAcsMd26SecRwLtStLegrstOtwdInwdPosMax.Val
          PA_KeSMSw4SAcsMd26SecRwLtStLegrstOtwdInwdPosMin_Val: accessed-parameter=KeSMSw4SAcsMd26SecRwLtStLegrstOtwdInwdPosMin.Val
          PA_KeSMSw4SLegrstCloseMdSecRwLtStLgrstOtwdInwdPos_Val: accessed-parameter=KeSMSw4SLegrstCloseMdSecRwLtStLgrstOtwdInwdPos.Val
          PA_KeSMSw4SLegrstCloseMdSecRwLtStLgrstOtwdInwdPosMax_Val: accessed-parameter=KeSMSw4SLegrstCloseMdSecRwLtStLgrstOtwdInwdPosMax.Val
          PA_KeSMSw4SLegrstCloseMdSecRwLtStLgrstOtwdInwdPosMin_Val: accessed-parameter=KeSMSw4SLegrstCloseMdSecRwLtStLgrstOtwdInwdPosMin.Val
          PA_KeSMSw4SLegrstOpenMdSecRwLtStLgrstOtwdInwdPos_Val: accessed-parameter=KeSMSw4SLegrstOpenMdSecRwLtStLgrstOtwdInwdPos.Val
          PA_KeSMSw4SLegrstOpenMdSecRwLtStLgrstOtwdInwdPosMax_Val: accessed-parameter=KeSMSw4SLegrstOpenMdSecRwLtStLgrstOtwdInwdPosMax.Val
          PA_KeSMSw4SLegrstOpenMdSecRwLtStLgrstOtwdInwdPosMin_Val: accessed-parameter=KeSMSw4SLegrstOpenMdSecRwLtStLgrstOtwdInwdPosMin.Val
          PA_KeSMSw4sLyingMDSecRwLtStLgrstOtwdInwdPos_160_Val: accessed-parameter=KeSMSw4sLyingMDSecRwLtStLgrstOtwdInwdPos_160.Val
          PA_KeSMSw4sLyingMDSecRwLtStLgrstOtwdInwdPos_165_Val: accessed-parameter=KeSMSw4sLyingMDSecRwLtStLgrstOtwdInwdPos_165.Val
          PA_KeSMSw4sLyingMDSecRwLtStLgrstOtwdInwdPos_170_Val: accessed-parameter=KeSMSw4sLyingMDSecRwLtStLgrstOtwdInwdPos_170.Val
          PA_KeSMSw4sLyingMDSecRwLtStLgrstOtwdInwdPos_175_Val: accessed-parameter=KeSMSw4sLyingMDSecRwLtStLgrstOtwdInwdPos_175.Val
          PA_KeSMSw4sLyingMDSecRwLtStLgrstOtwdInwdPos_180_Val: accessed-parameter=KeSMSw4sLyingMDSecRwLtStLgrstOtwdInwdPos_180.Val
          PA_KeSMSw4sLyingMDSecRwLtStLgrstOtwdInwdPos_Below160_Val: accessed-parameter=KeSMSw4sLyingMDSecRwLtStLgrstOtwdInwdPos_Below160.Val
          PA_KeSMSw4sLyingMDSecRwLtStLgrstOtwdInwdPos_Over180_Val: accessed-parameter=KeSMSw4sLyingMDSecRwLtStLgrstOtwdInwdPos_Over180.Val
          PA_KeSMSw4sLyingMDSecRwLtStLgrstOtwdInwdPosMax_160_Val: accessed-parameter=KeSMSw4sLyingMDSecRwLtStLgrstOtwdInwdPosMax_160.Val
          PA_KeSMSw4sLyingMDSecRwLtStLgrstOtwdInwdPosMax_165_Val: accessed-parameter=KeSMSw4sLyingMDSecRwLtStLgrstOtwdInwdPosMax_165.Val
          PA_KeSMSw4sLyingMDSecRwLtStLgrstOtwdInwdPosMax_170_Val: accessed-parameter=KeSMSw4sLyingMDSecRwLtStLgrstOtwdInwdPosMax_170.Val
          PA_KeSMSw4sLyingMDSecRwLtStLgrstOtwdInwdPosMax_175_Val: accessed-parameter=KeSMSw4sLyingMDSecRwLtStLgrstOtwdInwdPosMax_175.Val
          PA_KeSMSw4sLyingMDSecRwLtStLgrstOtwdInwdPosMax_180_Val: accessed-parameter=KeSMSw4sLyingMDSecRwLtStLgrstOtwdInwdPosMax_180.Val
          PA_KeSMSw4sLyingMDSecRwLtStLgrstOtwdInwdPosMax_Below160_Val: accessed-parameter=KeSMSw4sLyingMDSecRwLtStLgrstOtwdInwdPosMax_Below160.Val
          PA_KeSMSw4sLyingMDSecRwLtStLgrstOtwdInwdPosMax_Over180_Val: accessed-parameter=KeSMSw4sLyingMDSecRwLtStLgrstOtwdInwdPosMax_Over180.Val
          PA_KeSMSw4sLyingMDSecRwLtStLgrstOtwdInwdPosMin_160_Val: accessed-parameter=KeSMSw4sLyingMDSecRwLtStLgrstOtwdInwdPosMin_160.Val
          PA_KeSMSw4sLyingMDSecRwLtStLgrstOtwdInwdPosMin_165_Val: accessed-parameter=KeSMSw4sLyingMDSecRwLtStLgrstOtwdInwdPosMin_165.Val
          PA_KeSMSw4sLyingMDSecRwLtStLgrstOtwdInwdPosMin_170_Val: accessed-parameter=KeSMSw4sLyingMDSecRwLtStLgrstOtwdInwdPosMin_170.Val
          PA_KeSMSw4sLyingMDSecRwLtStLgrstOtwdInwdPosMin_175_Val: accessed-parameter=KeSMSw4sLyingMDSecRwLtStLgrstOtwdInwdPosMin_175.Val
          PA_KeSMSw4sLyingMDSecRwLtStLgrstOtwdInwdPosMin_180_Val: accessed-parameter=KeSMSw4sLyingMDSecRwLtStLgrstOtwdInwdPosMin_180.Val
          PA_KeSMSw4sLyingMDSecRwLtStLgrstOtwdInwdPosMin_Below160_Val: accessed-parameter=KeSMSw4sLyingMDSecRwLtStLgrstOtwdInwdPosMin_Below160.Val
          PA_KeSMSw4sLyingMDSecRwLtStLgrstOtwdInwdPosMin_Over180_Val: accessed-parameter=KeSMSw4sLyingMDSecRwLtStLgrstOtwdInwdPosMin_Over180.Val
          PA_KeSMSw4sRecoveryMDSecRwLtStLgrstOtwdInwdPos_160_Val: accessed-parameter=KeSMSw4sRecoveryMDSecRwLtStLgrstOtwdInwdPos_160.Val
          PA_KeSMSw4sRecoveryMDSecRwLtStLgrstOtwdInwdPos_165_Val: accessed-parameter=KeSMSw4sRecoveryMDSecRwLtStLgrstOtwdInwdPos_165.Val
          PA_KeSMSw4sRecoveryMDSecRwLtStLgrstOtwdInwdPos_170_Val: accessed-parameter=KeSMSw4sRecoveryMDSecRwLtStLgrstOtwdInwdPos_170.Val
          PA_KeSMSw4sRecoveryMDSecRwLtStLgrstOtwdInwdPos_175_Val: accessed-parameter=KeSMSw4sRecoveryMDSecRwLtStLgrstOtwdInwdPos_175.Val
          PA_KeSMSw4sRecoveryMDSecRwLtStLgrstOtwdInwdPos_180_Val: accessed-parameter=KeSMSw4sRecoveryMDSecRwLtStLgrstOtwdInwdPos_180.Val
          PA_KeSMSw4sRecoveryMDSecRwLtStLgrstOtwdInwdPos_Below160_Val: accessed-parameter=KeSMSw4sRecoveryMDSecRwLtStLgrstOtwdInwdPos_Below160.Val
          PA_KeSMSw4sRecoveryMDSecRwLtStLgrstOtwdInwdPos_Over180_Val: accessed-parameter=KeSMSw4sRecoveryMDSecRwLtStLgrstOtwdInwdPos_Over180.Val
          PA_KeSMSw4sRecoveryMDSecRwLtStLgrstOtwdInwdPosMax_160_Val: accessed-parameter=KeSMSw4sRecoveryMDSecRwLtStLgrstOtwdInwdPosMax_160.Val
          PA_KeSMSw4sRecoveryMDSecRwLtStLgrstOtwdInwdPosMax_165_Val: accessed-parameter=KeSMSw4sRecoveryMDSecRwLtStLgrstOtwdInwdPosMax_165.Val
          PA_KeSMSw4sRecoveryMDSecRwLtStLgrstOtwdInwdPosMax_170_Val: accessed-parameter=KeSMSw4sRecoveryMDSecRwLtStLgrstOtwdInwdPosMax_170.Val
          PA_KeSMSw4sRecoveryMDSecRwLtStLgrstOtwdInwdPosMax_175_Val: accessed-parameter=KeSMSw4sRecoveryMDSecRwLtStLgrstOtwdInwdPosMax_175.Val
          PA_KeSMSw4sRecoveryMDSecRwLtStLgrstOtwdInwdPosMax_180_Val: accessed-parameter=KeSMSw4sRecoveryMDSecRwLtStLgrstOtwdInwdPosMax_180.Val
          PA_KeSMSw4sRecoveryMDSecRwLtStLgrstOtwdInwdPosMax_Below160_Val: accessed-parameter=KeSMSw4sRecoveryMDSecRwLtStLgrstOtwdInwdPosMax_Below160.Val
          PA_KeSMSw4sRecoveryMDSecRwLtStLgrstOtwdInwdPosMax_Over180_Val: accessed-parameter=KeSMSw4sRecoveryMDSecRwLtStLgrstOtwdInwdPosMax_Over180.Val
          PA_KeSMSw4sRecoveryMDSecRwLtStLgrstOtwdInwdPosMin_160_Val: accessed-parameter=KeSMSw4sRecoveryMDSecRwLtStLgrstOtwdInwdPosMin_160.Val
          PA_KeSMSw4sRecoveryMDSecRwLtStLgrstOtwdInwdPosMin_165_Val: accessed-parameter=KeSMSw4sRecoveryMDSecRwLtStLgrstOtwdInwdPosMin_165.Val
          PA_KeSMSw4sRecoveryMDSecRwLtStLgrstOtwdInwdPosMin_170_Val: accessed-parameter=KeSMSw4sRecoveryMDSecRwLtStLgrstOtwdInwdPosMin_170.Val
          PA_KeSMSw4sRecoveryMDSecRwLtStLgrstOtwdInwdPosMin_175_Val: accessed-parameter=KeSMSw4sRecoveryMDSecRwLtStLgrstOtwdInwdPosMin_175.Val
          PA_KeSMSw4sRecoveryMDSecRwLtStLgrstOtwdInwdPosMin_180_Val: accessed-parameter=KeSMSw4sRecoveryMDSecRwLtStLgrstOtwdInwdPosMin_180.Val
          PA_KeSMSw4sRecoveryMDSecRwLtStLgrstOtwdInwdPosMin_Below160_Val: accessed-parameter=KeSMSw4sRecoveryMDSecRwLtStLgrstOtwdInwdPosMin_Below160.Val
          PA_KeSMSw4sRecoveryMDSecRwLtStLgrstOtwdInwdPosMin_Over180_Val: accessed-parameter=KeSMSw4sRecoveryMDSecRwLtStLgrstOtwdInwdPosMin_Over180.Val
          PA_KeSMSw4sVIPMDSecRwLtStLgrstOtwdInwdPos_160_Val: accessed-parameter=KeSMSw4sVIPMDSecRwLtStLgrstOtwdInwdPos_160.Val
          PA_KeSMSw4sVIPMDSecRwLtStLgrstOtwdInwdPos_165_Val: accessed-parameter=KeSMSw4sVIPMDSecRwLtStLgrstOtwdInwdPos_165.Val
          PA_KeSMSw4sVIPMDSecRwLtStLgrstOtwdInwdPos_170_Val: accessed-parameter=KeSMSw4sVIPMDSecRwLtStLgrstOtwdInwdPos_170.Val
          PA_KeSMSw4sVIPMDSecRwLtStLgrstOtwdInwdPos_175_Val: accessed-parameter=KeSMSw4sVIPMDSecRwLtStLgrstOtwdInwdPos_175.Val
          PA_KeSMSw4sVIPMDSecRwLtStLgrstOtwdInwdPos_180_Val: accessed-parameter=KeSMSw4sVIPMDSecRwLtStLgrstOtwdInwdPos_180.Val
          PA_KeSMSw4sVIPMDSecRwLtStLgrstOtwdInwdPos_Below160_Val: accessed-parameter=KeSMSw4sVIPMDSecRwLtStLgrstOtwdInwdPos_Below160.Val
          PA_KeSMSw4sVIPMDSecRwLtStLgrstOtwdInwdPos_Over180_Val: accessed-parameter=KeSMSw4sVIPMDSecRwLtStLgrstOtwdInwdPos_Over180.Val
          PA_KeSMSw4sVIPMDSecRwLtStLgrstOtwdInwdPosMax_160_Val: accessed-parameter=KeSMSw4sVIPMDSecRwLtStLgrstOtwdInwdPosMax_160.Val
          PA_KeSMSw4sVIPMDSecRwLtStLgrstOtwdInwdPosMax_165_Val: accessed-parameter=KeSMSw4sVIPMDSecRwLtStLgrstOtwdInwdPosMax_165.Val
          PA_KeSMSw4sVIPMDSecRwLtStLgrstOtwdInwdPosMax_170_Val: accessed-parameter=KeSMSw4sVIPMDSecRwLtStLgrstOtwdInwdPosMax_170.Val
          PA_KeSMSw4sVIPMDSecRwLtStLgrstOtwdInwdPosMax_175_Val: accessed-parameter=KeSMSw4sVIPMDSecRwLtStLgrstOtwdInwdPosMax_175.Val
          PA_KeSMSw4sVIPMDSecRwLtStLgrstOtwdInwdPosMax_180_Val: accessed-parameter=KeSMSw4sVIPMDSecRwLtStLgrstOtwdInwdPosMax_180.Val
          PA_KeSMSw4sVIPMDSecRwLtStLgrstOtwdInwdPosMax_Below160_Val: accessed-parameter=KeSMSw4sVIPMDSecRwLtStLgrstOtwdInwdPosMax_Below160.Val
          PA_KeSMSw4sVIPMDSecRwLtStLgrstOtwdInwdPosMax_Over180_Val: accessed-parameter=KeSMSw4sVIPMDSecRwLtStLgrstOtwdInwdPosMax_Over180.Val
          PA_KeSMSw4sVIPMDSecRwLtStLgrstOtwdInwdPosMin_160_Val: accessed-parameter=KeSMSw4sVIPMDSecRwLtStLgrstOtwdInwdPosMin_160.Val
          PA_KeSMSw4sVIPMDSecRwLtStLgrstOtwdInwdPosMin_165_Val: accessed-parameter=KeSMSw4sVIPMDSecRwLtStLgrstOtwdInwdPosMin_165.Val
          PA_KeSMSw4sVIPMDSecRwLtStLgrstOtwdInwdPosMin_170_Val: accessed-parameter=KeSMSw4sVIPMDSecRwLtStLgrstOtwdInwdPosMin_170.Val
          PA_KeSMSw4sVIPMDSecRwLtStLgrstOtwdInwdPosMin_175_Val: accessed-parameter=KeSMSw4sVIPMDSecRwLtStLgrstOtwdInwdPosMin_175.Val
          PA_KeSMSw4sVIPMDSecRwLtStLgrstOtwdInwdPosMin_180_Val: accessed-parameter=KeSMSw4sVIPMDSecRwLtStLgrstOtwdInwdPosMin_180.Val
          PA_KeSMSw4sVIPMDSecRwLtStLgrstOtwdInwdPosMin_Below160_Val: accessed-parameter=KeSMSw4sVIPMDSecRwLtStLgrstOtwdInwdPosMin_Below160.Val
          PA_KeSMSw4sVIPMDSecRwLtStLgrstOtwdInwdPosMin_Over180_Val: accessed-parameter=KeSMSw4sVIPMDSecRwLtStLgrstOtwdInwdPosMin_Over180.Val
          PA_KeSMSw6sAcsEntrySecRwLtStLgrstInwdOtwdPos_Val: accessed-parameter=KeSMSw6sAcsEntrySecRwLtStLgrstInwdOtwdPos.Val
          PA_KeSMSw6sAcsEntrySecRwLtStLgrstInwdOtwdPosMax_Val: accessed-parameter=KeSMSw6sAcsEntrySecRwLtStLgrstInwdOtwdPosMax.Val
          PA_KeSMSw6sAcsEntrySecRwLtStLgrstInwdOtwdPosMin_Val: accessed-parameter=KeSMSw6sAcsEntrySecRwLtStLgrstInwdOtwdPosMin.Val
          PA_KeSMSw6sRecoveryMdSecRwLtStLgrstInwdOtwdPos_Val: accessed-parameter=KeSMSw6sRecoveryMdSecRwLtStLgrstInwdOtwdPos.Val
          PA_KeSMSw6sRecoveryMdSecRwLtStLgrstInwdOtwdPosMax_Val: accessed-parameter=KeSMSw6sRecoveryMdSecRwLtStLgrstInwdOtwdPosMax.Val
          PA_KeSMSw6sRecoveryMdSecRwLtStLgrstInwdOtwdPosMin_Val: accessed-parameter=KeSMSw6sRecoveryMdSecRwLtStLgrstInwdOtwdPosMin.Val
          PA_KeSMSw6SVIPMdSecRwLtStLgrstInwdOtwdPos_Val: accessed-parameter=KeSMSw6SVIPMdSecRwLtStLgrstInwdOtwdPos.Val
          PA_KeSMSw6SVIPMdSecRwLtStLgrstInwdOtwdPosMax_Val: accessed-parameter=KeSMSw6SVIPMdSecRwLtStLgrstInwdOtwdPosMax.Val
          PA_KeSMSw6SVIPMdSecRwLtStLgrstInwdOtwdPosMin_Val: accessed-parameter=KeSMSw6SVIPMdSecRwLtStLgrstInwdOtwdPosMin.Val
          PA_KeSMSwAcsEntrySecRwLtStLgrstInwdOtwdPos_Val: accessed-parameter=KeSMSwAcsEntrySecRwLtStLgrstInwdOtwdPos.Val
          PA_KeSMSwAcsEntrySecRwLtStLgrstInwdOtwdPosMax_Val: accessed-parameter=KeSMSwAcsEntrySecRwLtStLgrstInwdOtwdPosMax.Val
          PA_KeSMSwAcsEntrySecRwLtStLgrstInwdOtwdPosMin_Val: accessed-parameter=KeSMSwAcsEntrySecRwLtStLgrstInwdOtwdPosMin.Val
          PA_KeSMSwAcsMd8SecRwLtStLgrstInwdOtwdPos_Val: accessed-parameter=KeSMSwAcsMd8SecRwLtStLgrstInwdOtwdPos.Val
          PA_KeSMSwAcsMd8SecRwLtStLgrstInwdOtwdPosMax_Val: accessed-parameter=KeSMSwAcsMd8SecRwLtStLgrstInwdOtwdPosMax.Val
          PA_KeSMSwAcsMd8SecRwLtStLgrstInwdOtwdPosMin_Val: accessed-parameter=KeSMSwAcsMd8SecRwLtStLgrstInwdOtwdPosMin.Val
          PA_KeSMSwRecoveryMdSecRwLtStLgrstInwdOtwdPos_Val: accessed-parameter=KeSMSwRecoveryMdSecRwLtStLgrstInwdOtwdPos.Val
          PA_KeSMSwRecoveryMdSecRwLtStLgrstInwdOtwdPosMax_Val: accessed-parameter=KeSMSwRecoveryMdSecRwLtStLgrstInwdOtwdPosMax.Val
          PA_KeSMSwRecoveryMdSecRwLtStLgrstInwdOtwdPosMin_Val: accessed-parameter=KeSMSwRecoveryMdSecRwLtStLgrstInwdOtwdPosMin.Val
          PA_KeSMSwVIPMdSecRwLtStLgrstInwdOtwdPos_Val: accessed-parameter=KeSMSwVIPMdSecRwLtStLgrstInwdOtwdPos.Val
          PA_KeSMSwVIPMdSecRwLtStLgrstInwdOtwdPosMax_Val: accessed-parameter=KeSMSwVIPMdSecRwLtStLgrstInwdOtwdPosMax.Val
          PA_KeSMSwVIPMdSecRwLtStLgrstInwdOtwdPosMin_Val: accessed-parameter=KeSMSwVIPMdSecRwLtStLgrstInwdOtwdPosMin.Val
  swc implementation SecRwLtStLgrstInwdOtwdTrgtPosSelc_Implementation: behavior=SecRwLtStLgrstInwdOtwdTrgtPosSelc_InternalBehavior
    code-descriptors:
      code Default: artifact-descriptors=autosar-engineering-object={short-label=Default, category=SWSRC}
package /PATAC/MSM/ModeAdjust/CalPortInterface
  7 x parameter interface:
    KeSMSw4SAcsMd22SecRwLtStLegrstOtwdInwdPos
      parameter data prototype Val: sw-calibration-access=READ-WRITE, type=UInt16
    KeSMSw4SAcsMd22SecRwLtStLegrstOtwdInwdPosMax
      parameter data prototype Val: sw-calibration-access=READ-WRITE, type=UInt16
    KeSMSw4SAcsMd22SecRwLtStLegrstOtwdInwdPosMin
      parameter data prototype Val: sw-calibration-access=READ-WRITE, type=UInt16
    KeSMSw4SAcsMd26SecRwLtStLegrstOtwdInwdPos
      parameter data prototype Val: sw-calibration-access=READ-WRITE, type=UInt16
    KeSMSw4SAcsMd26SecRwLtStLegrstOtwdInwdPosMax
      parameter data prototype Val: sw-calibration-access=READ-WRITE, type=UInt16
    KeSMSw4SAcsMd26SecRwLtStLegrstOtwdInwdPosMin
      parameter data prototype Val: sw-calibration-access=READ-WRITE, type=UInt16
    Pos
      parameter data prototype Val: sw-calibration-access=READ-WRITE, type=UInt16
package /PATAC/MSM/ModeAdjust/DataType
  impl type TrgtPosCalibArray: category=ARRAY, sw-calibration-access=READ-ONLY, type-emitter=RTE  # 0:pos 1:max 2:min
    element Element: array-size=3, array-size-semantics=FIXED-SIZE, implementation-data-type=UInt16, invalid-value=0
package /PATAC/MSM/ModeAdjust/PortInterface
  client server interface SecRwLtStLgrstInwdOtwdTrgtPosSelc
    operation Cal
  client server interface VIPL557TrgtPos
    operation Get
      5 x arg, all with type=UInt16, direction=OUT, server-argument-impl-policy=USE-ARGUMENT-TYPE:
        SecRwLtStBkReclnTrgtPos
        SecRwLtStZeroTrgtPos
        SecRwLtStLgrstUpwdDnwdTrgtPos
        SecRwLtStLgrstInwdOtwdTrgtPos
        SecRwLtStFwdBkwdTrgtPos
    operation Set
      5 x arg, all with type=UInt16, direction=IN, server-argument-impl-policy=USE-ARGUMENT-TYPE:
        SecRwLtStBkReclnTrgtPos
        SecRwLtStZeroTrgtPos
        SecRwLtStLgrstUpwdDnwdTrgtPos
        SecRwLtStLgrstInwdOtwdTrgtPos
        SecRwLtStFwdBkwdTrgtPos
  client server interface VIPLExit557TrgtPos
    operation Get
      7 x arg, all with type=UInt16, direction=OUT, server-argument-impl-policy=USE-ARGUMENT-TYPE:
        SecRwLtStBkReclnTrgtPos
        SecRwLtStZeroTrgtPos
        SecRwLtStLgrstUpwdDnwdTrgtPos
        SecRwLtStLgrstInwdOtwdTrgtPos
        ThdRwLtStBkReclnTrgtPos
        ThdRwLtStFwdBkwdTrgtPos
        SecRwLtStFwdBkwdTrgtPos
    operation Set
  sender receiver interface HeightIndex: invalidation-policy{data-element=HeightIndex/Val, handle-invalid=DONT-INVALIDATE}
    data Val: type=UInt8  # 0：under 160 1：160 2：165 3：170 4：175 5：180 6：over 180
  sender receiver interface StNumFlg
    4 x data, all with type=Boolean:
      Is4s
      Is6s
      Is6s7s
      Is7s
    invalidation-policys:
      data-element=Is4s, handle-invalid=DONT-INVALIDATE
      data-element=Is6s, handle-invalid=DONT-INVALIDATE
      data-element=Is6s7s, handle-invalid=DONT-INVALIDATE
      data-element=Is7s, handle-invalid=DONT-INVALIDATE
  sender receiver interface TrgtPosCalibArray: invalidation-policy{data-element=TrgtPosArray, handle-invalid=DONT-INVALIDATE}
    data TrgtPosArray: type=TrgtPosCalibArray  # 0:Pos 1:Max 2:Min
package /PATAC/MSM/PortInterfaces
  sender receiver interface IfVeSMSbSecRwLtStCshnFrntUpwdDnwdMovConfig: invalidation-policy{data-element=IfVeSMSbSecRwLtStCshnFrntUpwdDnwdMovConfig/Val, handle-invalid=DONT-INVALIDATE}
    data Val: type=Boolean
